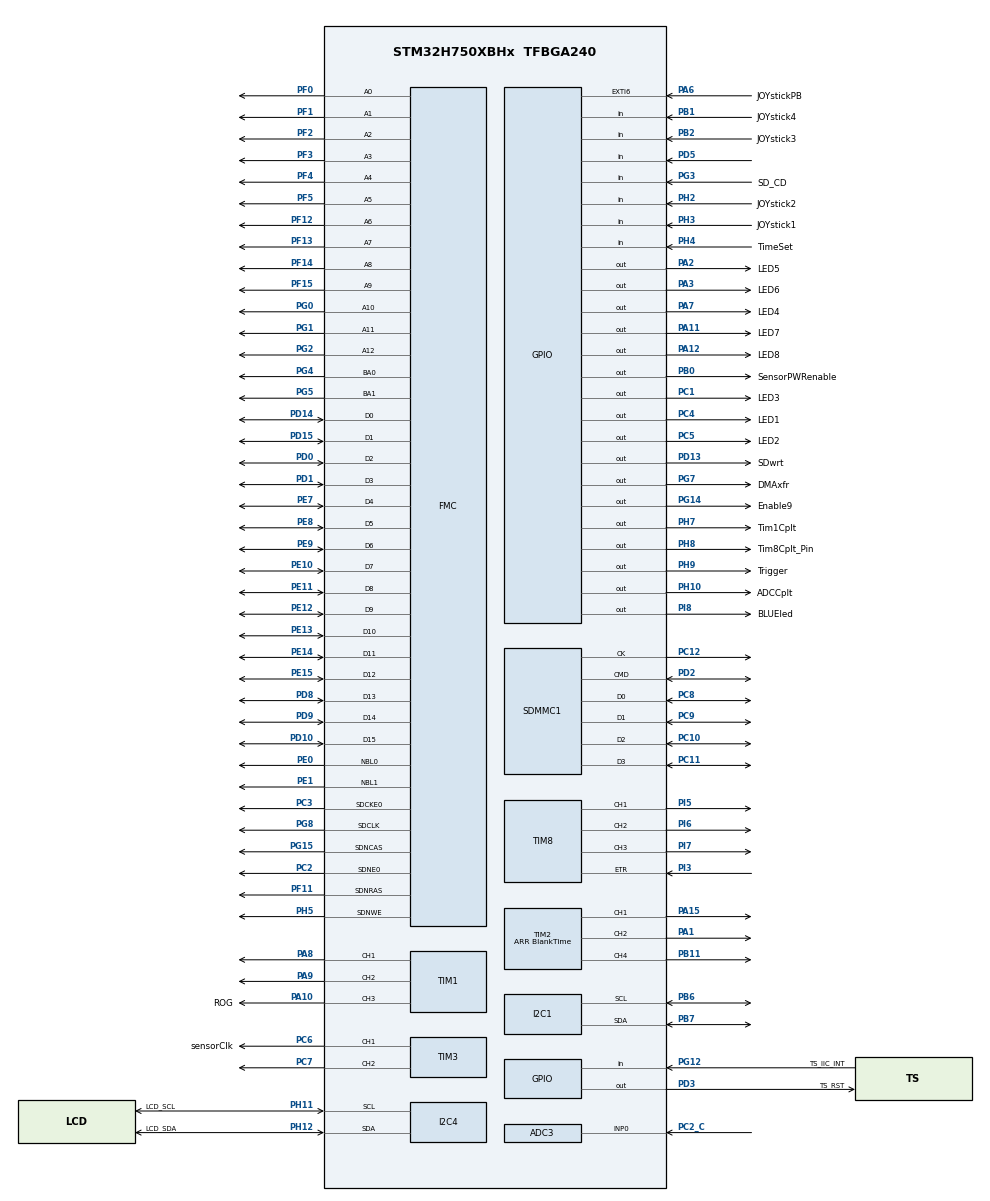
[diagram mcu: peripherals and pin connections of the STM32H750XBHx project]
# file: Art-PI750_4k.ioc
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ADC3.Channel-0\#ChannelRegularConversion=ADC_CHANNEL_0
ADC3.ClockPrescalerADC3=ADC_CLOCK_SYNC_PCLK_DIV1
ADC3.ConversionDataManagement=ADC_CONVERSIONDATA_DMA_CIRCULAR
ADC3.ExternalTrigConv=ADC_EXTERNALTRIG_T8_TRGO2
ADC3.ExternalTrigConvEdge=ADC_EXTERNALTRIGCONVEDGE_RISING
ADC3.LeftBitShift=ADC_LEFTBITSHIFT_4
ADC3.NbrOfConversionFlag=1
ADC3.OffsetNumber-0\#ChannelRegularConversion=ADC_OFFSET_NONE
ADC3.OffsetSignedSaturation-0\#ChannelRegularConversion=DISABLE
ADC3.Overrun=ADC_OVR_DATA_OVERWRITTEN
ADC3.Rank-0\#ChannelRegularConversion=1
ADC3.Resolution=ADC_RESOLUTION_12B
ADC3.SamplingTime-0\#ChannelRegularConversion=ADC_SAMPLETIME_1CYCLE_5
Bdma.I2C4_RX.1.Direction=DMA_PERIPH_TO_MEMORY
Bdma.I2C4_RX.1.EventEnable=DISABLE
Bdma.I2C4_RX.1.Instance=BDMA_Channel1
Bdma.I2C4_RX.1.MemDataAlignment=DMA_MDATAALIGN_BYTE
Bdma.I2C4_RX.1.MemInc=DMA_MINC_ENABLE
Bdma.I2C4_RX.1.Mode=DMA_NORMAL
Bdma.I2C4_RX.1.PeriphDataAlignment=DMA_PDATAALIGN_BYTE
Bdma.I2C4_RX.1.PeriphInc=DMA_PINC_DISABLE
Bdma.I2C4_RX.1.Polarity=HAL_DMAMUX_REQ_GEN_RISING
Bdma.I2C4_RX.1.Priority=DMA_PRIORITY_LOW
Bdma.I2C4_RX.1.RequestNumber=1
Bdma.I2C4_RX.1.SignalID=NONE
Bdma.I2C4_RX.1.SyncEnable=DISABLE
Bdma.I2C4_RX.1.SyncPolarity=HAL_DMAMUX_SYNC_NO_EVENT
Bdma.I2C4_RX.1.SyncRequestNumber=1
Bdma.I2C4_RX.1.SyncSignalID=NONE
Bdma.I2C4_TX.0.Direction=DMA_MEMORY_TO_PERIPH
Bdma.I2C4_TX.0.EventEnable=ENABLE
Bdma.I2C4_TX.0.Instance=BDMA_Channel0
Bdma.I2C4_TX.0.MemDataAlignment=DMA_MDATAALIGN_BYTE
Bdma.I2C4_TX.0.MemInc=DMA_MINC_ENABLE
Bdma.I2C4_TX.0.Mode=DMA_NORMAL
Bdma.I2C4_TX.0.PeriphDataAlignment=DMA_PDATAALIGN_BYTE
Bdma.I2C4_TX.0.PeriphInc=DMA_PINC_DISABLE
Bdma.I2C4_TX.0.Polarity=HAL_DMAMUX_REQ_GEN_RISING
Bdma.I2C4_TX.0.Priority=DMA_PRIORITY_LOW
Bdma.I2C4_TX.0.RequestNumber=1
Bdma.I2C4_TX.0.SignalID=NONE
Bdma.I2C4_TX.0.SyncEnable=DISABLE
Bdma.I2C4_TX.0.SyncPolarity=HAL_DMAMUX_SYNC_NO_EVENT
Bdma.I2C4_TX.0.SyncRequestNumber=1
Bdma.I2C4_TX.0.SyncSignalID=NONE
Bdma.Request0=I2C4_TX
Bdma.Request1=I2C4_RX
Bdma.RequestsNb=2
Dma.ADC3.1.Direction=DMA_PERIPH_TO_MEMORY
Dma.ADC3.1.EventEnable=DISABLE
Dma.ADC3.1.FIFOMode=DMA_FIFOMODE_ENABLE
Dma.ADC3.1.FIFOThreshold=DMA_FIFO_THRESHOLD_HALFFULL
Dma.ADC3.1.Instance=DMA2_Stream7
Dma.ADC3.1.MemBurst=DMA_MBURST_SINGLE
Dma.ADC3.1.MemDataAlignment=DMA_MDATAALIGN_HALFWORD
Dma.ADC3.1.MemInc=DMA_MINC_ENABLE
Dma.ADC3.1.Mode=DMA_CIRCULAR
Dma.ADC3.1.PeriphBurst=DMA_PBURST_SINGLE
Dma.ADC3.1.PeriphDataAlignment=DMA_PDATAALIGN_HALFWORD
Dma.ADC3.1.PeriphInc=DMA_PINC_DISABLE
Dma.ADC3.1.Polarity=HAL_DMAMUX_REQ_GEN_RISING
Dma.ADC3.1.Priority=DMA_PRIORITY_VERY_HIGH
Dma.ADC3.1.RequestNumber=1
Dma.ADC3.1.SignalID=NONE
Dma.ADC3.1.SyncEnable=DISABLE
Dma.ADC3.1.SyncPolarity=HAL_DMAMUX_SYNC_NO_EVENT
Dma.ADC3.1.SyncRequestNumber=1
Dma.ADC3.1.SyncSignalID=NONE
Dma.MEMTOMEM.0.Direction=DMA_MEMORY_TO_MEMORY
Dma.MEMTOMEM.0.EventEnable=DISABLE
Dma.MEMTOMEM.0.FIFOMode=DMA_FIFOMODE_ENABLE
Dma.MEMTOMEM.0.FIFOThreshold=DMA_FIFO_THRESHOLD_FULL
Dma.MEMTOMEM.0.Instance=DMA1_Stream7
Dma.MEMTOMEM.0.MemBurst=DMA_MBURST_INC4
Dma.MEMTOMEM.0.MemDataAlignment=DMA_MDATAALIGN_WORD
Dma.MEMTOMEM.0.MemInc=DMA_MINC_ENABLE
Dma.MEMTOMEM.0.Mode=DMA_NORMAL
Dma.MEMTOMEM.0.PeriphBurst=DMA_PBURST_INC4
Dma.MEMTOMEM.0.PeriphDataAlignment=DMA_PDATAALIGN_WORD
Dma.MEMTOMEM.0.PeriphInc=DMA_PINC_ENABLE
Dma.MEMTOMEM.0.Polarity=HAL_DMAMUX_REQ_GEN_RISING
Dma.MEMTOMEM.0.Priority=DMA_PRIORITY_VERY_HIGH
Dma.MEMTOMEM.0.RequestNumber=1
Dma.MEMTOMEM.0.SignalID=NONE
Dma.MEMTOMEM.0.SyncEnable=DISABLE
Dma.MEMTOMEM.0.SyncPolarity=HAL_DMAMUX_SYNC_NO_EVENT
Dma.MEMTOMEM.0.SyncRequestNumber=1
Dma.MEMTOMEM.0.SyncSignalID=NONE
Dma.Request0=MEMTOMEM
Dma.Request1=ADC3
FATFS.BSP.number=1
FATFS.USE_DMA_CODE_SD=1
FATFS._FS_EXFAT=1
FATFS._USE_LFN=1
FATFS0.BSP.STBoard=false
FATFS0.BSP.api=Unknown
FATFS0.BSP.instance=PG3
FATFS0.BSP.ip=GPIO
FATFS0.BSP.mode=Input
FATFS0.BSP.name=Detect_SDIO
FATFS0.BSP.solution=PG3
FMC.CASLatency1=FMC_SDRAM_CAS_LATENCY_2
FMC.ColumnBitsNumber1=FMC_SDRAM_COLUMN_BITS_NUM_9
FMC.ExitSelfRefreshDelay1=7
FMC.LoadToActiveDelay1=2
FMC.RCDDelay1=2
FMC.RPDelay1=2
FMC.ReadBurst1=FMC_SDRAM_RBURST_ENABLE
FMC.ReadPipeDelay1=FMC_SDRAM_RPIPE_DELAY_2
FMC.ReadPipeDelay2=FMC_SDRAM_RPIPE_DELAY_2
FMC.RowCycleDelay1=6
FMC.RowCycleDelay2=6
FMC.SDClockPeriod1=FMC_SDRAM_CLOCK_PERIOD_2
FMC.SDClockPeriod2=FMC_SDRAM_CLOCK_PERIOD_2
FMC.SelfRefreshTime1=5
FMC.WriteRecoveryTime1=3
I2C1.Timing=0x00C0EAFF
Mcu.Family=STM32H7
Mcu.Name=STM32H750XBHx
Mcu.Package=TFBGA240
Mcu.UserConstants=BlankTime,(1800-1);Usec,100;TIMEDenom,8;Exposure,(8000);NumLines,1000;TIMENumer,5;Npixels,4096
Mdma.MDMA_Channel0.Request0=SDMMC1_COMMAND_END
Mdma.MDMA_Channel0.RequestsNb=1
Mdma.MDMA_Channel0.SDMMC1_COMMAND_END.0.BlockCount=0
Mdma.MDMA_Channel0.SDMMC1_COMMAND_END.0.BlockDataLength=0
Mdma.MDMA_Channel0.SDMMC1_COMMAND_END.0.BufferTransferLength=1
Mdma.MDMA_Channel0.SDMMC1_COMMAND_END.0.CircularMode=MDMA_LINEAR_LIST
Mdma.MDMA_Channel0.SDMMC1_COMMAND_END.0.DataAlignment=MDMA_DATAALIGN_PACKENABLE
Mdma.MDMA_Channel0.SDMMC1_COMMAND_END.0.DestBlockAddressOffset=0
Mdma.MDMA_Channel0.SDMMC1_COMMAND_END.0.DestBurst=MDMA_DEST_BURST_SINGLE
Mdma.MDMA_Channel0.SDMMC1_COMMAND_END.0.DestDataSize=MDMA_DEST_DATASIZE_WORD
Mdma.MDMA_Channel0.SDMMC1_COMMAND_END.0.DestinationInc=MDMA_DEST_INC_WORD
Mdma.MDMA_Channel0.SDMMC1_COMMAND_END.0.DstAddress=0
Mdma.MDMA_Channel0.SDMMC1_COMMAND_END.0.Endianness=MDMA_LITTLE_ENDIANNESS_PRESERVE
Mdma.MDMA_Channel0.SDMMC1_COMMAND_END.0.Instance=MDMA_Channel0
Mdma.MDMA_Channel0.SDMMC1_COMMAND_END.0.MaskAddress=0
Mdma.MDMA_Channel0.SDMMC1_COMMAND_END.0.MaskData=0
Mdma.MDMA_Channel0.SDMMC1_COMMAND_END.0.Priority=MDMA_PRIORITY_LOW
Mdma.MDMA_Channel0.SDMMC1_COMMAND_END.0.Rank=First
Mdma.MDMA_Channel0.SDMMC1_COMMAND_END.0.SourceBlockAddressOffset=0
Mdma.MDMA_Channel0.SDMMC1_COMMAND_END.0.SourceBurst=MDMA_SOURCE_BURST_SINGLE
Mdma.MDMA_Channel0.SDMMC1_COMMAND_END.0.SourceDataSize=MDMA_SRC_DATASIZE_WORD
Mdma.MDMA_Channel0.SDMMC1_COMMAND_END.0.SourceInc=MDMA_SRC_INC_WORD
Mdma.MDMA_Channel0.SDMMC1_COMMAND_END.0.SrcAddress=0
Mdma.MDMA_Channel0.SDMMC1_COMMAND_END.0.TransferTriggerMode=MDMA_BUFFER_TRANSFER
Mdma.RequestSet0=MDMA_Channel0
Mdma.RequestSetsNb=1
NVIC.ADC3_IRQn=true\:0\:0\:false\:false\:true\:true\:true\:true
NVIC.BDMA_Channel0_IRQn=true\:0\:0\:false\:false\:true\:false\:true\:true
NVIC.BDMA_Channel1_IRQn=true\:0\:0\:false\:false\:true\:false\:true\:true
NVIC.DMA1_Stream7_IRQn=true\:0\:0\:false\:false\:true\:true\:true\:true
NVIC.DMA2_Stream7_IRQn=true\:0\:0\:false\:false\:true\:false\:true\:true
NVIC.DMAMUX2_OVR_IRQn=true\:0\:0\:false\:false\:true\:false\:true\:true
NVIC.I2C4_ER_IRQn=true\:0\:0\:false\:false\:true\:true\:true\:true
NVIC.I2C4_EV_IRQn=true\:0\:0\:false\:false\:true\:true\:true\:true
NVIC.MDMA_IRQn=true\:0\:0\:false\:false\:true\:false\:true\:true
NVIC.PriorityGroup=NVIC_PRIORITYGROUP_4
NVIC.SDMMC1_IRQn=true\:0\:0\:false\:false\:true\:true\:true\:true
NVIC.TIM1_TRG_COM_IRQn=true\:0\:0\:false\:false\:true\:true\:true\:true
NVIC.TIM1_UP_IRQn=true\:0\:0\:false\:false\:true\:true\:true\:true
NVIC.TIM2_IRQn=true\:0\:0\:false\:false\:true\:true\:true\:true
NVIC.TIM3_IRQn=true\:0\:0\:false\:false\:true\:true\:true\:true
NVIC.TIM8_TRG_COM_TIM14_IRQn=true\:0\:0\:false\:false\:true\:true\:true\:true
NVIC.TIM8_UP_TIM13_IRQn=true\:0\:0\:false\:false\:true\:true\:true\:true
PA1.GPIO_Speed=GPIO_SPEED_FREQ_HIGH
PA1.Signal=S_TIM2_CH2
PA10.GPIO_Label=ROG
PA10.GPIO_Speed=GPIO_SPEED_FREQ_HIGH
PA10.Signal=S_TIM1_CH3
PA11.GPIO_Label=LED7
PA11.Signal=GPIO_Output
PA12.GPIO_Label=LED8
PA12.Signal=GPIO_Output
PA15\ (JTDI).GPIO_Speed=GPIO_SPEED_FREQ_HIGH
PA15\ (JTDI).Signal=S_TIM2_CH1_ETR
PA2.GPIO_Label=LED5
PA2.Signal=GPIO_Output
PA3.GPIO_Label=LED6
PA3.GPIO_PuPd=GPIO_PULLDOWN
PA3.Signal=GPIO_Output
PA6.GPIO_Label=JOYstickPB
PA6.GPIO_PuPd=GPIO_PULLUP
PA6.Signal=GPXTI6
PA7.GPIO_Label=LED4
PA7.Signal=GPIO_Output
PA8.GPIO_Speed=GPIO_SPEED_FREQ_HIGH
PA8.Signal=S_TIM1_CH1
PA9.GPIO_Speed=GPIO_SPEED_FREQ_HIGH
PA9.Signal=S_TIM1_CH2
PB0.GPIO_Label=SensorPWRenable
PB0.PinState=GPIO_PIN_SET
PB0.Signal=GPIO_Output
PB1.GPIO_Label=JOYstick4
PB1.GPIO_PuPd=GPIO_PULLUP
PB1.Signal=GPIO_Input
PB10.Signal=USART3_TX
PB11.Signal=S_TIM2_CH4
PB2.GPIO_Label=JOYstick3
PB2.GPIO_PuPd=GPIO_PULLUP
PB2.Signal=GPIO_Input
PB3\ (JTDO/TRACESWO).Signal=SDMMC2_D2
PB6.Mode=I2C
PB6.Signal=I2C1_SCL
PB7.Mode=I2C
PB7.Signal=I2C1_SDA
PC1.GPIO_Label=LED3
PC1.Signal=GPIO_Output
PC10.Mode=SD_4_bits_Wide_bus
PC10.Signal=SDMMC1_D2
PC11.Mode=SD_4_bits_Wide_bus
PC11.Signal=SDMMC1_D3
PC12.Mode=SD_4_bits_Wide_bus
PC12.Signal=SDMMC1_CK
PC14-OSC32_IN\ (OSC32_IN).Mode=LSE-External-Oscillator
PC14-OSC32_IN\ (OSC32_IN).Signal=RCC_OSC32_IN
PC15-OSC32_OUT\ (OSC32_OUT).Mode=LSE-External-Oscillator
PC15-OSC32_OUT\ (OSC32_OUT).Signal=RCC_OSC32_OUT
PC2.Mode=SdramChipSelect1_1
PC2.Signal=FMC_SDNE0
PC2_C.Mode=IN0-Single-Ended
PC2_C.Signal=ADC3_INP0
PC3.Mode=SdramChipSelect1_1
PC3.Signal=FMC_SDCKE0
PC4.GPIO_Label=LED1
PC4.Signal=GPIO_Output
PC5.GPIO_Label=LED2
PC5.Signal=GPIO_Output
PC6.GPIO_Label=sensorClk
PC6.GPIO_Speed=GPIO_SPEED_FREQ_HIGH
PC6.Signal=S_TIM3_CH1
PC7.GPIO_Speed=GPIO_SPEED_FREQ_HIGH
PC7.Signal=S_TIM3_CH2
PC8.Mode=SD_4_bits_Wide_bus
PC8.Signal=SDMMC1_D0
PC9.Mode=SD_4_bits_Wide_bus
PC9.Signal=SDMMC1_D1
PD0.Signal=FMC_D2_DA2
PD1.Signal=FMC_D3_DA3
PD10.Signal=FMC_D15_DA15
PD13.GPIO_Label=SDwrt
PD13.Signal=GPIO_Output
PD14.Signal=FMC_D0_DA0
PD15.Signal=FMC_D1_DA1
PD2.Mode=SD_4_bits_Wide_bus
PD2.Signal=SDMMC1_CMD
PD3.GPIO_Label=TS_RST
PD3.Signal=GPIO_Output
PD5.Signal=GPIO_Input
PD8.Signal=FMC_D13_DA13
PD9.Signal=FMC_D14_DA14
PE0.Signal=FMC_NBL0
PE1.Signal=FMC_NBL1
PE10.Signal=FMC_D7_DA7
PE11.Signal=FMC_D8_DA8
PE12.Signal=FMC_D9_DA9
PE13.Signal=FMC_D10_DA10
PE14.Signal=FMC_D11_DA11
PE15.Signal=FMC_D12_DA12
PE7.Signal=FMC_D4_DA4
PE8.Signal=FMC_D5_DA5
PE9.Signal=FMC_D6_DA6
PF0.Signal=FMC_A0
PF1.Signal=FMC_A1
PF11.Signal=FMC_SDNRAS
PF12.Signal=FMC_A6
PF13.Signal=FMC_A7
PF14.Signal=FMC_A8
PF15.Signal=FMC_A9
PF2.Signal=FMC_A2
PF3.Signal=FMC_A3
PF4.Signal=FMC_A4
PF5.Signal=FMC_A5
PF7.Signal=QUADSPI_BK1_IO2
PG0.Signal=FMC_A10
PG1.Signal=FMC_A11
PG12.GPIO_Label=TS_IIC_INT
PG12.GPIO_PuPd=GPIO_PULLUP
PG12.Signal=GPIO_Input
PG14.GPIO_Label=Enable9
PG14.GPIO_PuPd=GPIO_PULLUP
PG14.Signal=GPIO_Output
PG15.Signal=FMC_SDNCAS
PG2.Signal=FMC_A12
PG3.GPIO_Label=SD_CD
PG3.GPIO_PuPd=GPIO_PULLDOWN
PG3.Signal=GPIO_Input
PG4.Signal=FMC_A14_BA0
PG5.Signal=FMC_A15_BA1
PG6.Signal=QUADSPI_BK1_NCS
PG7.GPIO_Label=DMAxfr
PG7.Signal=GPIO_Output
PG8.Signal=FMC_SDCLK
PH0-OSC_IN\ (PH0).Mode=HSE-External-Oscillator
PH0-OSC_IN\ (PH0).Signal=RCC_OSC_IN
PH1-OSC_OUT\ (PH1).Mode=HSE-External-Oscillator
PH1-OSC_OUT\ (PH1).Signal=RCC_OSC_OUT
PH10.GPIO_Label=ADCCplt
PH10.Signal=GPIO_Output
PH11.GPIO_Label=LCD_SCL
PH11.Mode=I2C
PH11.Signal=I2C4_SCL
PH12.GPIO_Label=LCD_SDA
PH12.Mode=I2C
PH12.Signal=I2C4_SDA
PH2.GPIO_Label=JOYstick2
PH2.GPIO_PuPd=GPIO_PULLUP
PH2.Signal=GPIO_Input
PH3.GPIO_Label=JOYstick1
PH3.GPIO_PuPd=GPIO_PULLUP
PH3.Signal=GPIO_Input
PH4.GPIO_Label=TimeSet
PH4.Signal=GPIO_Input
PH5.Signal=FMC_SDNWE
PH7.GPIO_Label=Tim1Cplt
PH7.Signal=GPIO_Output
PH8.GPIO_Label=Tim8Cplt_Pin
PH8.Signal=GPIO_Output
PH9.GPIO_Label=Trigger
PH9.Signal=GPIO_Output
PI12.Signal=LTDC_HSYNC
PI13.Signal=LTDC_VSYNC
PI14.Signal=LTDC_CLK
PI15.Signal=LTDC_R0
PI3.Signal=S_TIM8_ETR
PI5.GPIO_Speed=GPIO_SPEED_FREQ_HIGH
PI5.Signal=S_TIM8_CH1
PI6.Signal=S_TIM8_CH2
PI7.Signal=S_TIM8_CH3
PI8.GPIO_Label=BLUEled
PI8.GPIO_PuPd=GPIO_PULLUP
PI8.Signal=GPIO_Output
PJ0.Signal=LTDC_R1
PJ1.Signal=LTDC_R2
PJ10.Signal=LTDC_G3
PJ11.Signal=LTDC_G4
PJ12.Signal=LTDC_B0
PJ13.Signal=LTDC_B1
PJ2.Signal=LTDC_R3
PJ3.Signal=LTDC_R4
PJ4.Signal=LTDC_R5
PJ6.Signal=LTDC_R7
PJ7.Signal=LTDC_G0
PJ8.Signal=LTDC_G1
PJ9.Signal=LTDC_G2
PK1.Signal=LTDC_G6
PK2.Signal=LTDC_G7
PK3.Signal=LTDC_B4
PK4.Signal=LTDC_B5
PK5.Signal=LTDC_B6
PK6.Signal=LTDC_B7
ProjectManager.HeapSize=0x800
ProjectManager.StackSize=0x1600
ProjectManager.TargetToolchain=STM32CubeIDE
RCC.ADCCLockSelection=RCC_ADCCLKSOURCE_PLL3
RCC.ADCFreq_Value=37500000
RCC.APB1Freq_Value=50000000
RCC.APB2Freq_Value=50000000
RCC.APB3Freq_Value=100000000
RCC.APB4Freq_Value=100000000
RCC.CortexFreq_Value=400000000
RCC.D1PPRE=RCC_APB3_DIV2
RCC.D2PPRE1=RCC_APB1_DIV4
RCC.D2PPRE2=RCC_APB2_DIV4
RCC.D3PPRE=RCC_APB4_DIV2
RCC.DIVM1=5
RCC.DIVM2=25
RCC.DIVM3=5
RCC.DIVN1=160
RCC.DIVN2=192
RCC.DIVN3=30
RCC.DIVP2=4
RCC.DIVQ1=20
RCC.DIVR2=5
RCC.DIVR3=4
RCC.FMCCLockSelection=RCC_FMCCLKSOURCE_PLL
RCC.HCLKFreq_Value=200000000
RCC.HPRE=RCC_HCLK_DIV2
RCC.I2C4CLockSelection=RCC_I2C4CLKSOURCE_HSI
RCC.PLLSourceVirtual=RCC_PLLSOURCE_HSE
RCC.PWR_Regulator_Voltage_Scale=PWR_REGULATOR_VOLTAGE_SCALE1
RCC.QSPICLockSelection=RCC_QSPICLKSOURCE_PLL
RCC.RTCClockSelection=RCC_RTCCLKSOURCE_LSE
RCC.SYSCLKFreq_VALUE=400000000
RCC.SYSCLKSource=RCC_SYSCLKSOURCE_PLLCLK
RCC.USBFreq_Value=40000000
RTC.Date=2
RTC.Hours=13
RTC.Minutes=30
RTC.Month=RTC_MONTH_NOVEMBER
RTC.StoreOperation=RTC_STOREOPERATION_SET
RTC.WeekDay=RTC_WEEKDAY_SUNDAY
RTC.Year=23
SDMMC1.ClockDiv=2
SDMMC1.HardwareFlowControl=SDMMC_HARDWARE_FLOW_CONTROL_DISABLE
SH.FMC_A0.0=FMC_A0,13b-sda1
SH.FMC_A1.0=FMC_A1,13b-sda1
SH.FMC_A10.0=FMC_A10,13b-sda1
SH.FMC_A11.0=FMC_A11,13b-sda1
SH.FMC_A12.0=FMC_A12,13b-sda1
SH.FMC_A14_BA0.0=FMC_BA0,FourSdramBanks1
SH.FMC_A15_BA1.0=FMC_BA1,FourSdramBanks1
SH.FMC_A2.0=FMC_A2,13b-sda1
SH.FMC_A3.0=FMC_A3,13b-sda1
SH.FMC_A4.0=FMC_A4,13b-sda1
SH.FMC_A5.0=FMC_A5,13b-sda1
SH.FMC_A6.0=FMC_A6,13b-sda1
SH.FMC_A7.0=FMC_A7,13b-sda1
SH.FMC_A8.0=FMC_A8,13b-sda1
SH.FMC_A9.0=FMC_A9,13b-sda1
SH.FMC_D0_DA0.0=FMC_D0,sd-16b-d1
SH.FMC_D10_DA10.0=FMC_D10,sd-16b-d1
SH.FMC_D11_DA11.0=FMC_D11,sd-16b-d1
SH.FMC_D12_DA12.0=FMC_D12,sd-16b-d1
SH.FMC_D13_DA13.0=FMC_D13,sd-16b-d1
SH.FMC_D14_DA14.0=FMC_D14,sd-16b-d1
SH.FMC_D15_DA15.0=FMC_D15,sd-16b-d1
SH.FMC_D1_DA1.0=FMC_D1,sd-16b-d1
SH.FMC_D2_DA2.0=FMC_D2,sd-16b-d1
SH.FMC_D3_DA3.0=FMC_D3,sd-16b-d1
SH.FMC_D4_DA4.0=FMC_D4,sd-16b-d1
SH.FMC_D5_DA5.0=FMC_D5,sd-16b-d1
SH.FMC_D6_DA6.0=FMC_D6,sd-16b-d1
SH.FMC_D7_DA7.0=FMC_D7,sd-16b-d1
SH.FMC_D8_DA8.0=FMC_D8,sd-16b-d1
SH.FMC_D9_DA9.0=FMC_D9,sd-16b-d1
SH.FMC_NBL0.0=FMC_NBL0,Sd2ByteEnable1
SH.FMC_NBL1.0=FMC_NBL1,Sd2ByteEnable1
SH.FMC_SDCLK.0=FMC_SDCLK,13b-sda1
SH.FMC_SDNCAS.0=FMC_SDNCAS,13b-sda1
SH.FMC_SDNRAS.0=FMC_SDNRAS,13b-sda1
SH.FMC_SDNWE.0=FMC_SDNWE,13b-sda1
SH.S_TIM1_CH1.0=TIM1_CH1,PWM Generation1 CH1
SH.S_TIM1_CH2.0=TIM1_CH2,PWM Generation2 CH2
SH.S_TIM1_CH3.0=TIM1_CH3,PWM Generation3 CH3
SH.S_TIM2_CH1_ETR.0=TIM2_CH1,PWM Generation1 CH1
SH.S_TIM2_CH2.0=TIM2_CH2,PWM Generation2 CH2
SH.S_TIM2_CH4.0=TIM2_CH4,PWM Generation4 CH4
SH.S_TIM3_CH1.0=TIM3_CH1,PWM Generation1 CH1
SH.S_TIM3_CH2.0=TIM3_CH2,PWM Generation2 CH2
SH.S_TIM8_CH1.0=TIM8_CH1,PWM Generation1 CH1
SH.S_TIM8_CH2.0=TIM8_CH2,PWM Generation2 CH2
SH.S_TIM8_CH3.0=TIM8_CH3,PWM Generation3 CH3
SH.S_TIM8_ETR.0=TIM8_ETR,TriggerSource_ETR
TIM1.AutoReloadPreload=TIM_AUTORELOAD_PRELOAD_ENABLE
TIM1.Channel-PWM\ Generation1\ CH1=TIM_CHANNEL_1
TIM1.Channel-PWM\ Generation2\ CH2=TIM_CHANNEL_2
TIM1.Channel-PWM\ Generation3\ CH3=TIM_CHANNEL_3
TIM1.OC2Preload_PWM=ENABLE
TIM1.OCFastMode_PWM-PWM\ Generation2\ CH2=TIM_OCFAST_ENABLE
TIM1.OCFastMode_PWM-PWM\ Generation3\ CH3=TIM_OCFAST_ENABLE
TIM1.OCIdleState_2=TIM_OCIDLESTATE_RESET
TIM1.OCMode_PWM-PWM\ Generation1\ CH1=TIM_OCMODE_PWM2
TIM1.OCMode_PWM-PWM\ Generation2\ CH2=TIM_OCMODE_PWM2
TIM1.OCMode_PWM-PWM\ Generation3\ CH3=TIM_OCMODE_PWM2
TIM1.OCPolarity_1=TIM_OCPOLARITY_LOW
TIM1.OCPolarity_2=TIM_OCPOLARITY_LOW
TIM1.OCPolarity_3=TIM_OCPOLARITY_LOW
TIM1.Period=((Exposure*TIMEDenom/TIMENumer)-1)
TIM1.Prescaler=((Usec*TIMENumer/TIMEDenom)-1)
TIM1.Pulse-PWM\ Generation1\ CH1=4
TIM1.Pulse-PWM\ Generation2\ CH2=3
TIM1.Pulse-PWM\ Generation3\ CH3=3
TIM1.RepetitionCounter=NumLines
TIM1.TIM_MasterOutputTrigger=TIM_TRGO_OC1REF
TIM1.TIM_MasterOutputTrigger2=TIM_TRGO2_UPDATE
TIM1.TIM_MasterSlaveMode=TIM_MASTERSLAVEMODE_ENABLE
TIM2.Channel-PWM\ Generation1\ CH1=TIM_CHANNEL_1
TIM2.Channel-PWM\ Generation2\ CH2=TIM_CHANNEL_2
TIM2.Channel-PWM\ Generation4\ CH4=TIM_CHANNEL_4
TIM2.OCFastMode_PWM-PWM\ Generation1\ CH1=TIM_OCFAST_ENABLE
TIM2.OCFastMode_PWM-PWM\ Generation2\ CH2=TIM_OCFAST_ENABLE
TIM2.OCMode_PWM-PWM\ Generation1\ CH1=TIM_OCMODE_PWM2
TIM2.OCMode_PWM-PWM\ Generation2\ CH2=TIM_OCMODE_PWM1
TIM2.OCPolarity_1=TIM_OCPOLARITY_HIGH
TIM2.Period=BlankTime
TIM2.Pulse-PWM\ Generation1\ CH1=Usec/3-1
TIM2.Pulse-PWM\ Generation2\ CH2=(Usec/4) -1
TIM2.TIM_MasterSlaveMode=TIM_MASTERSLAVEMODE_ENABLE
TIM3.Channel-PWM\ Generation1\ CH1=TIM_CHANNEL_1
TIM3.Channel-PWM\ Generation2\ CH2=TIM_CHANNEL_2
TIM3.OCMode_PWM-PWM\ Generation2\ CH2=TIM_OCMODE_PWM1
TIM3.OCPolarity_1=TIM_OCPOLARITY_HIGH
TIM3.OCPolarity_2=TIM_OCPOLARITY_HIGH
TIM3.Period=(Usec*TIMENumer/TIMEDenom-1)
TIM3.Pulse-PWM\ Generation1\ CH1=((Usec/4)-1)
TIM3.Pulse-PWM\ Generation2\ CH2=(((Usec/4))-1)
TIM3.TIM_MasterOutputTrigger=TIM_TRGO_OC3REF
TIM8.Channel-PWM\ Generation1\ CH1=TIM_CHANNEL_1
TIM8.Channel-PWM\ Generation2\ CH2=TIM_CHANNEL_2
TIM8.Channel-PWM\ Generation3\ CH3=TIM_CHANNEL_3
TIM8.OCFastMode_PWM-PWM\ Generation1\ CH1=TIM_OCFAST_ENABLE
TIM8.OCFastMode_PWM-PWM\ Generation2\ CH2=TIM_OCFAST_ENABLE
TIM8.OCFastMode_PWM-PWM\ Generation3\ CH3=TIM_OCFAST_ENABLE
TIM8.OCMode_PWM-PWM\ Generation1\ CH1=TIM_OCMODE_PWM2
TIM8.OCMode_PWM-PWM\ Generation2\ CH2=TIM_OCMODE_PWM2
TIM8.OCMode_PWM-PWM\ Generation3\ CH3=TIM_OCMODE_PWM2
TIM8.Period=(Usec*TIMENumer/TIMEDenom)-1
TIM8.Pulse-PWM\ Generation1\ CH1=((Usec/4)-1)
TIM8.Pulse-PWM\ Generation2\ CH2=2
TIM8.Pulse-PWM\ Generation3\ CH3=2
TIM8.RepetitionCounter=Npixels-1
TIM8.TIM_MasterOutputTrigger=TIM_TRGO_UPDATE
TIM8.TIM_MasterOutputTrigger2=TIM_TRGO2_OC1REF
TIM8.TIM_MasterSlaveMode=TIM_MASTERSLAVEMODE_ENABLE
VP_FATFS_VS_SDIO.Mode=SDIO
VP_MEMORYMAP_VS_MEMORYMAP.Mode=CurAppReg
VP_RTC_VS_RTC_Activate.Mode=RTC_Enabled
VP_RTC_VS_RTC_Calendar.Mode=RTC_Calendar
VP_TIM1_VS_ClockSourceINT.Mode=Internal
VP_TIM1_VS_OPM.Mode=OPM_bit
VP_TIM2_VS_ClockSourceINT.Mode=Internal
VP_TIM2_VS_ClockSourceITR.Mode=TriggerSource_ITR0
VP_TIM2_VS_ControllerModeTrigger.Mode=Trigger Mode
VP_TIM2_VS_OPM.Mode=OPM_bit
VP_TIM3_VS_ClockSourceINT.Mode=Internal
VP_TIM3_VS_ClockSourceITR.Mode=TriggerSource_ITR0
VP_TIM3_VS_ControllerModeGated.Mode=Gated Mode
VP_TIM8_VS_ClockSourceINT.Mode=Internal
VP_TIM8_VS_ControllerModeTrigger.Mode=Trigger Mode
VP_TIM8_VS_OPM.Mode=OPM_bit
VP_VREFBUF_V_VREFBUF.Mode=ExternalMode
board=custom

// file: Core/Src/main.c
/* USER CODE BEGIN Header */
/**
 ******************************************************************************
 * @file           : main.c
 * @brief          : Main program body
 ******************************************************************************
 * @attention
 *
 * Timer rational
 * Tim1 -> Master clock 				Provides ROG
 * Tim2 -> Blank time Tiggered by #1
 * Tim3 -> Gatemode   Triggered by #2  	Provides SensorClk
 * Tim8 -> 								Provides  trigger Ext trigger by 3 to ADC
 * ADC triggers DMA to Buffer D2
 * ADC Complete triggers DMA from D2 to SDram
 *
 *
 *
 ******************************************************************************
 */
/* USER CODE END Header */
#include "main.h"
#include "adc.h"
#include "bdma.h"
#include "dma.h"
#include "fatfs.h"
#include "i2c.h"
#include "mdma.h"
#include "memorymap.h"
#include "rtc.h"
#include "sdmmc.h"
#include "tim.h"
#include "gpio.h"
#include "fmc.h"

/* USER CODE BEGIN Includes */
#include <stdio.h>
#include <string.h>
#include "memtest.h"
#include "ssd1306.h"

/* USER CODE END Includes */

/* USER CODE BEGIN PD */
#define DMA_BUFFER   __attribute__((section(".sdram")))
#define DMAd2BUFFER   __attribute__((section(".dma_buffer")))

#define DMABUFFLEN (Npixels*2)

#define SLOTS ((30*1024*1024 /(Npixels*2)))
//#define TIMENumer 6
//#define TIMEDenom 8
#define ONEPWR
//#define  WRSLOTS 16

enum Seq{ SEQ_Ready=0,SEQ_Running,SEQ_ONgoing,SEQ_Complete};
enum ADC_state{ADC_idle,ADC_1half,ADC_2half };
enum SD_state{SDnotopen,SDopen};
enum SelectN_slc{SelectNNOTSelectNed,SelectNSelectNed};
enum ChoiceS{SelectN_RUN,SelectN_EXP,SelectN_LGTH};
enum XferReady {NotReady,Ready};
enum RUNSTATE {CONTINUOUS,SINGLE,HISTOGRAM,HALT};
//#define HALFCPLT_ADC_GPIO 	HAL_GPIO_TogglePin(ADChalfCplt_GPIO_Port, ADChalfCplt_Pin);

#define CPLT_TIM1pe_GPIO	HAL_GPIO_TogglePin(GPIOH, Tim1Cplt_Pin)
#define CPLT_TIM8pe_GPIO	HAL_GPIO_TogglePin(GPIOH, Tim8Cplt_Pin)
#define CPLT_ADC_GPIO		HAL_GPIO_TogglePin(GPIOH, ADCCplt_Pin)

#define TRIGGER_TIM1_GPIO	HAL_GPIO_TogglePin(GPIOH, Trigger_Pin)
#define DMA_XFR_CPLT_GPIO   HAL_GPIO_TogglePin(GPIOG, DMAxfr_Pin)
#define SD_WriteStartTime   HAL_GPIO_TogglePin(GPIOD, SDwrt_Pin)

#define SDRAMAREA 0xc0000000

#define DISK
#define  LCD_ShowString(a, b, c,d, e, f) {ssd1306_SetCursor(a, b); ssd1306_WriteString(f, Font_7x10);	   ssd1306_UpdateScreen();}
/* USER CODE END PD */

/* USER CODE BEGIN PV */

volatile uint16_t  *DMA_2nBuffer;
FIL fp;
char rtext[_MAX_SS] = "1234567890 1234567890 ";;
//char whitespace [234];
char fileHeadertext[_MAX_SS];
uint8_t FontH;// = Font_7x10.FontHeight;
GPIO_PinState buttonState=0;
GPIO_PinState oldState=0;
uint8_t Sequence=SEQ_Ready;
uint8_t ADCstate=ADC_idle;
uint8_t SDstate=SDnotopen;
uint8_t RunState = HALT;
uint8_t xferState = NotReady;
int8_t MenuItem =0;
int8_t SelectNEState = 1;
uint16_t SelectNEStateValue[]={6000,7000,8000,9000,10000,12000};
int8_t SelectNLState = 2;
uint16_t SelectNLStateValue[]={4096,8192,16384,32768};

char RunType[]={'C','S','H'};
uint8_t SelectRT=2;
uint32_t DACval=0;

FRESULT f_err_code;
static FATFS FATFS_Obj;

int Nfilename=0;
FIL fp;
uint32_t BytesWritten=0;
int hlen;
volatile DMAd2BUFFER uint16_t dmaBuffer[DMABUFFLEN];

#ifdef Exposure
#undef Exposure
#undef NumLines
#endif
uint32_t Exposure ;
uint32_t NumLines ;
RTC_TimeTypeDef timeStart;
RTC_TimeTypeDef timeEnd;
RTC_TimeTypeDef Filetime;
uint32_t secStart=0;
uint16_t lastpixel=0;
volatile uint32_t IRQCNT_HAL_UART_TxCpltCallback=0;
volatile uint32_t IRQCNT_HAL_ADC_ConvCpltCallback=0;
volatile uint32_t IRQCNT_HAL_TIM_PeriodElapsedHalfCpltCallback1=0;
volatile uint32_t IRQCNT_HAL_TIM_PeriodElapsedHalfCpltCallback2=0;
volatile uint32_t IRQCNT_HAL_TIM_PeriodElapsedHalfCpltCallback3=0;
volatile uint32_t IRQCNT_HAL_TIM_PeriodElapsedHalfCpltCallback8=0;
volatile uint32_t IRQCNT_HAL_TIM_PeriodElapsedCallback1=0;
volatile uint32_t IRQCNT_HAL_TIM_PeriodElapsedCallback2=0;
volatile uint32_t IRQCNT_HAL_TIM_PeriodElapsedCallback3=0;
volatile uint32_t IRQCNT_HAL_TIM_PeriodElapsedCallback8=0;
volatile uint32_t IRQCNT_HAL_TIM_TriggerCallback1=0;
volatile uint32_t IRQCNT_HAL_TIM_TriggerCallback2=0;
volatile uint32_t IRQCNT_HAL_TIM_TriggerCallback3=0;
volatile uint32_t IRQCNT_HAL_TIM_TriggerCallback8=0;

volatile uint32_t TransferComplete7=0;
volatile uint32_t TransferCompleteelse=0;

volatile uint32_t HAL_GPIO_EXTI_CallbackK1=0;
volatile uint32_t HAL_GPIO_EXTI_CallbackSelectN=0;

volatile uint32_t HAL_GPIO_EXTI_CallbackNxt=0;

volatile uint32_t pixelPlaceOld, pixelPlace;
volatile uint32_t BuffDiff=0,BuffDiffMax=0;
volatile uint32_t CurrentSlot=0;
volatile uint32_t LastWrittenSlot=0;
volatile uint32_t NumberOfWrites=0;

/* USER CODE END PV */

void SystemClock_Config(void);
/* USER CODE BEGIN PFP */
void TransferComplete(DMA_HandleTypeDef *hdma);
void TransferError(DMA_HandleTypeDef *hdma);
void TrialEnd(void);
/* USER CODE END PFP */

/* USER CODE BEGIN 0 */

int RTC_Set(
		uint8_t year, uint8_t month, uint8_t day,
		uint8_t hour, uint8_t min)
{
	HAL_StatusTypeDef res;
	RTC_TimeTypeDef time;
	RTC_DateTypeDef date;

	memset(&time, 0, sizeof(time));
	memset(&date, 0, sizeof(date));

	date.WeekDay = 0;
	date.Year = year;
	date.Month = month;
	date.Date = day;

	res = HAL_RTC_SetDate(&hrtc, &date, RTC_FORMAT_BIN);
	if(res != HAL_OK) {
		Error_Handler();
	}

	time.Hours = hour;
	time.Minutes = min;
	time.Seconds = 0;

	res = HAL_RTC_SetTime(&hrtc, &time, RTC_FORMAT_BIN);
	if(res != HAL_OK) {
		Error_Handler();
	}

	return 0;
}
//=========================================================================================================================

//volatile uint8_t keyval=0;

uint8_t JOYstickPOS()
{
	uint8_t	keyval=0;
	keyval = HAL_GPIO_ReadPin (JOYstickPB_GPIO_Port,JOYstickPB_Pin)<<4 ;
	keyval +=		HAL_GPIO_ReadPin (GPIOB, JOYstick4_Pin)<<3 ;
	keyval +=		HAL_GPIO_ReadPin (GPIOB, JOYstick3_Pin)<<2 ;
	keyval +=		HAL_GPIO_ReadPin (GPIOH, JOYstick2_Pin)<<1 ;
	keyval +=		HAL_GPIO_ReadPin (GPIOH, JOYstick1_Pin) ;
	keyval = (~keyval) & 0x1f;

	return keyval;
}
void ledDisp(uint8_t Localval)
{
	if(0x01 & Localval)
		HAL_GPIO_WritePin(GPIOC, LED1_Pin, GPIO_PIN_SET);
	else
		HAL_GPIO_WritePin(GPIOC, LED1_Pin, GPIO_PIN_RESET);
	if(0x02 & Localval)
		HAL_GPIO_WritePin(GPIOC, LED2_Pin, GPIO_PIN_SET);
	else
		HAL_GPIO_WritePin(GPIOC, LED2_Pin, GPIO_PIN_RESET);
	if(0x04 & Localval)
		HAL_GPIO_WritePin(GPIOC, LED3_Pin, GPIO_PIN_SET);
	else
		HAL_GPIO_WritePin(GPIOC, LED3_Pin, GPIO_PIN_RESET);
	if(0x08 & Localval)
		HAL_GPIO_WritePin(GPIOA, LED4_Pin, GPIO_PIN_SET);
	else
		HAL_GPIO_WritePin(GPIOA, LED4_Pin, GPIO_PIN_RESET);
	if(0x10 & Localval)
		HAL_GPIO_WritePin(GPIOA, LED5_Pin, GPIO_PIN_SET);
	else
		HAL_GPIO_WritePin(GPIOA, LED5_Pin, GPIO_PIN_RESET);
	if(0x20 & Localval)
		HAL_GPIO_WritePin(GPIOA, LED6_Pin, GPIO_PIN_SET);
	else
		HAL_GPIO_WritePin(GPIOA, LED6_Pin, GPIO_PIN_RESET);
	if(0x40 & Localval)
		HAL_GPIO_WritePin(GPIOA, LED7_Pin, GPIO_PIN_SET);
	else
		HAL_GPIO_WritePin(GPIOA, LED7_Pin, GPIO_PIN_RESET);
	if(0x80 & Localval)
		HAL_GPIO_WritePin(GPIOA, LED8_Pin, GPIO_PIN_SET);
	else
		HAL_GPIO_WritePin(GPIOA, LED8_Pin, GPIO_PIN_RESET);

}
void setTime()
{
	int8_t Jsp=0,TimeItem=0;
	int8_t TimeArray[12];
	RTC_DateTypeDef FILEdate;
	RTC_TimeTypeDef FILEtime;
	HAL_StatusTypeDef res;

	ssd1306_Clear();

	res = HAL_RTC_GetTime(&hrtc, &FILEtime, RTC_FORMAT_BIN);
	if(res != HAL_OK) {
		Error_Handler();
	}

	res = HAL_RTC_GetDate(&hrtc, &FILEdate, RTC_FORMAT_BIN);
	if(res != HAL_OK) {
		Error_Handler();
	}
    TimeArray[0] =(FILEdate.Year  /10) %10;
    TimeArray[1] =(FILEdate.Year - TimeArray[0])%10;

    TimeArray[2] =(FILEdate.Month /10)%10;
    TimeArray[3] =(FILEdate.Month - TimeArray[2])%10;

    TimeArray[4] =(FILEdate.Date /10)%10;
    TimeArray[5] =(FILEdate.Date - TimeArray[4])%10;

    TimeArray[6] =(FILEtime.Hours /10)%10;
    TimeArray[7] =(FILEtime.Hours - TimeArray[6])%10;

    TimeArray[8] =(FILEtime.Minutes /10)%10;
    TimeArray[9] =(FILEtime.Minutes - TimeArray[8])%10;

	while (1)
	{
		sprintf(rtext, "%4d / %2d / %2d",
				2000+TimeArray[0]*10+TimeArray[1],
				TimeArray[2]*10+TimeArray[3],
				TimeArray[4]*10+TimeArray[5]);
		LCD_ShowString(2, 0, 6,8 , White, rtext);
		sprintf(rtext," %2d:%2d",
				TimeArray[6]*10+TimeArray[7],
				TimeArray[8]*10+TimeArray[9]);
		LCD_ShowString(2, FontH*2, 6,8 , White, rtext);
		Jsp = JOYstickPOS();
		HAL_Delay(25);
		switch (Jsp){
		case (1):{   //R
			if (TimeItem == 9) {TimeItem = 0;} else TimeItem++ ;
			break;
		}
		case (4):{  //L
			if (TimeItem>0) {TimeItem-- ;}
			else MenuItem =9;
			break;
		}
		case (16):{ //UP
			TimeArray[TimeItem] == 9 ? TimeArray[TimeItem]=0: TimeArray[TimeItem]++;
			break;
		}
		case (8):{ //DN
			TimeArray[TimeItem] == 0 ? TimeArray[TimeItem]=9 :TimeArray[TimeItem]--;
			break;
		}
		case (2):{
			RTC_Set(TimeArray[0]*10+TimeArray[1],
					TimeArray[2]*10+TimeArray[3],
					TimeArray[4]*10+TimeArray[5],
					TimeArray[6]*10+TimeArray[7],
					TimeArray[8]*10+TimeArray[9]);

			ssd1306_Clear();

			return;
			break;
		}

		}

	}

}
//=========================================================================================================================

void *memset16(void *m, uint16_t val, size_t count)
{
	uint16_t *buf = m;

	while(count--) *buf++ = val;
	return m;
}

//=========================================================================================================================
void ProcessBlock()
{
	uint32_t hist[128];
	uint32_t sharp[128];
	memset(hist,0,128*sizeof(uint32_t));
	memset(sharp,0,128*sizeof(uint32_t));
	uint32_t CS = CurrentSlot %SLOTS ? (CurrentSlot-2) %SLOTS : CurrentSlot %SLOTS ;
	uint16_t *linptr = (uint16_t *)(SDRAMAREA+((CS%SLOTS)*(Npixels*2)));
	uint32_t norm =0;//,zero=0;
	uint32_t pindex;
	uint32_t partialdiff;//,oldp;

	for (int i=0 ; i < Npixels ;i++){
		pindex = linptr[i];

		pindex = pindex>>9; //segments of 128(of 65536)
		if (pindex > 127) pindex = 127;
		hist[pindex]++;

		if (norm < hist[pindex])
			  norm = hist[pindex]; //find local max

		partialdiff = abs((int32_t)linptr[i] - (int32_t)linptr[i+1]);
		if (partialdiff > sharp[i/(Npixels>>7)] )
			sharp[i/(Npixels>>7)] = partialdiff;
	}
	ssd1306_Clear();

	for (int i=0 ;i<128;i++){
		if (hist[i] != 0)
		{
			uint32_t v= hist[i]*48/norm;
			ssd1306_DrawVerticalLine(i, (int16_t)48-v ,(int16_t) v);
		}
		uint32_t w = sharp[i]>>10;
		ssd1306_DrawVerticalLine(i, (int16_t)64-w ,(int16_t) w);

	}

	ssd1306_UpdateScreen();

	//	printf("norm %d , Zeros %d\n",norm,zero);

}
//=========================================================================================================================
void Histo()
{
	ssd1306_Clear();
	//HAL_GPIO_WritePin(REDled_GPIO_Port, REDled_Pin, GPIO_PIN_SET); //Clear Error light
	TransferComplete7=0;
	TransferCompleteelse=0;
			if (HAL_OK !=  HAL_TIM_PWM_Stop(&htim1, TIM_CHANNEL_1))Error_Handler(); //reload Exposure& Length
			if (HAL_OK !=  HAL_TIM_PWM_Stop(&htim1, TIM_CHANNEL_2))Error_Handler(); //reload Exposure& Length
			if (HAL_OK !=  HAL_TIM_PWM_Stop(&htim1, TIM_CHANNEL_3))Error_Handler(); //reload Exposure& Length
//			HAL_TIM_Base_Stop(&htim1);
//			HAL_TIM_Base_Stop_IT(&htim1);

	htim1.Init.Period = (Exposure*TIMEDenom/TIMENumer)-1;
	htim1.Init.RepetitionCounter = NumLines-1;
	if (HAL_TIM_Base_Init(&htim1) != HAL_OK)Error_Handler();

	Sequence=SEQ_Running;
	CurrentSlot=0;
	LastWrittenSlot=0;
	HAL_TIM_Base_Start(&htim2);HAL_TIM_Base_Start(&htim3);HAL_TIM_Base_Start(&htim8);

	if (HAL_OK !=   HAL_TIM_PWM_Start(&htim1, TIM_CHANNEL_1))Error_Handler();
	if (HAL_OK !=   HAL_TIM_PWM_Start(&htim1, TIM_CHANNEL_2))Error_Handler();
	if (HAL_OK !=   HAL_TIM_PWM_Start(&htim1, TIM_CHANNEL_3))Error_Handler();
//	HAL_TIM_Base_Start(&htim1);
//	HAL_TIM_Base_Start_IT(&htim1);

	HAL_Delay(80);
	oldState = GPIO_PIN_SET;
	{
		while(RunState != HALT && (SEQ_Complete != Sequence)){
			if (CurrentSlot >2)ProcessBlock();
			if (0 != JOYstickPOS()){
				RunState = HALT;
				Sequence=SEQ_Complete;
			}
		}

	}
	TrialEnd();

}//complete

//----------------------------------------------------------------------------
void TrialStart()
{
	if( SDstate == SDnotopen)
	{
		ssd1306_Clear();
//		IRQCNT_HAL_UART_TxCpltCallback=0;
		IRQCNT_HAL_ADC_ConvCpltCallback=0;
//		IRQCNT_HAL_TIM_PeriodElapsedHalfCpltCallback1=0;
//		IRQCNT_HAL_TIM_PeriodElapsedHalfCpltCallback2=0;
//		IRQCNT_HAL_TIM_PeriodElapsedHalfCpltCallback3=0;
//		IRQCNT_HAL_TIM_PeriodElapsedHalfCpltCallback8=0;
//		IRQCNT_HAL_TIM_PeriodElapsedCallback1=0;
//		IRQCNT_HAL_TIM_PeriodElapsedCallback2=0;
//		IRQCNT_HAL_TIM_PeriodElapsedCallback3=0;
//		IRQCNT_HAL_TIM_PeriodElapsedCallback8=0;
//		IRQCNT_HAL_TIM_TriggerCallback1=0;
//		IRQCNT_HAL_TIM_TriggerCallback2=0;
//		IRQCNT_HAL_TIM_TriggerCallback3=0;
//		IRQCNT_HAL_TIM_TriggerCallback8=0;
//		HAL_GPIO_WritePin(REDled_GPIO_Port, REDled_Pin, GPIO_PIN_SET); //Clear Error light
		TransferComplete7=0;
		TransferCompleteelse=0;
		DACval=0;BuffDiffMax=0;
#ifdef DISK
		f_err_code = f_mount( &FATFS_Obj, (TCHAR const*)SDPath,0);
		if (f_err_code != FR_OK )
		{
			printf("Diskerror%d /n",f_err_code);
			{
				Error_Handler();
			}
		}
#endif
		HAL_TIM_Base_Start(&htim2);HAL_TIM_Base_Start(&htim3);HAL_TIM_Base_Start(&htim8);

				if (HAL_OK !=  HAL_TIM_PWM_Stop(&htim1, TIM_CHANNEL_1))Error_Handler(); //reload Exposure& Length
				if (HAL_OK !=  HAL_TIM_PWM_Stop(&htim1, TIM_CHANNEL_2))Error_Handler(); //reload Exposure& Length
				if (HAL_OK !=  HAL_TIM_PWM_Stop(&htim1, TIM_CHANNEL_3))Error_Handler(); //reload Exposure& Length
//				HAL_TIM_Base_Stop(&htim1);
//				HAL_TIM_Base_Stop_IT(&htim1);

		htim1.Init.Period = (Exposure*TIMEDenom/TIMENumer)-1;
		htim1.Init.RepetitionCounter = NumLines-1;
		if (HAL_TIM_Base_Init(&htim1) != HAL_OK)Error_Handler();

		RTC_DateTypeDef FILEdate;
		HAL_StatusTypeDef res;

		res = HAL_RTC_GetTime(&hrtc, &Filetime, RTC_FORMAT_BIN);
		if(res != HAL_OK) Error_Handler();

		res = HAL_RTC_GetDate(&hrtc, &FILEdate, RTC_FORMAT_BIN);
		if(res != HAL_OK) Error_Handler();

		HAL_Delay(800);

		sprintf((char *)rtext,"0:%02d%02d%02d%02d%02d%02d_%02d.pgm",
				FILEdate.Year,
				FILEdate.Month,
				FILEdate.Date,
				Filetime.Hours,
				Filetime.Minutes,
				Filetime.Seconds,
				SelectNEStateValue[SelectNEState]/1000);
#ifdef DISK
		f_err_code = f_open(&fp,( char *)rtext,FA_CREATE_ALWAYS | FA_READ | FA_WRITE);
		HAL_Delay(800);
		if (f_err_code != 		FR_OK	){
			LCD_ShowString(2, 0, 6,8, White, "FC Error");
			f_close(&fp);
			Error_Handler();
		}
//
//		sprintf((char *)fileHeadertext,"P5 %5d %5d 65535 ", Npixels,SelectNLStateValue[SelectNLState] );
//		int hlen = strlen(fileHeadertext);
//		res = f_write ( &fp,
//				(const void*) fileHeadertext ,
//				hlen ,
//				(void *)&BytesWritten);
//		if (res  != 0 || (BytesWritten != (hlen))	){
//			LCD_ShowString(2, 0, 6,8,White, "FW Error");
//			f_close(&fp);
//			Error_Handler();
//		}

#endif
		secStart=((uint32_t)Filetime.Hours*3600)+((uint32_t)Filetime.Minutes*60)+(uint32_t)Filetime.Seconds;
		LCD_ShowString(2, FontH, 6, 8, White,rtext);

		SDstate=SDopen;
		sprintf((char *)rtext,"Run %d %d  ",SelectNEStateValue[SelectNEState],SelectNLStateValue[SelectNLState]);
		LCD_ShowString(2, 0, 6,8 , White, rtext);
		NumberOfWrites =0;
		Sequence=SEQ_Running;

		CurrentSlot=0;
		LastWrittenSlot=0;
		HAL_TIM_Base_Start(&htim2);HAL_TIM_Base_Start(&htim3);HAL_TIM_Base_Start(&htim8);
			if (HAL_OK !=   HAL_TIM_PWM_Start(&htim1, TIM_CHANNEL_1))Error_Handler();
			if (HAL_OK !=   HAL_TIM_PWM_Start(&htim1, TIM_CHANNEL_2))Error_Handler();
			if (HAL_OK !=   HAL_TIM_PWM_Start(&htim1, TIM_CHANNEL_3))Error_Handler();
//			HAL_TIM_Base_Start(&htim1);
//			HAL_TIM_Base_Start_IT(&htim1);

		oldState = GPIO_PIN_SET;
	}
}
//=========================================================================================================================
void TrialEnd()
{
	if (SDstate == SDopen)
	{
#ifdef DISK
		f_close(&fp);
#endif
	}

			if (HAL_OK !=  HAL_TIM_PWM_Stop(&htim1, TIM_CHANNEL_1))Error_Handler(); //reload Exposure& Length
			if (HAL_OK !=  HAL_TIM_PWM_Stop(&htim1, TIM_CHANNEL_2))Error_Handler(); //reload Exposure& Length
			if (HAL_OK !=  HAL_TIM_PWM_Stop(&htim1, TIM_CHANNEL_3))Error_Handler(); //reload Exposure& Length
			HAL_TIM_Base_Stop(&htim2);HAL_TIM_Base_Stop(&htim3);HAL_TIM_Base_Stop(&htim8);
//			HAL_TIM_Base_Stop(&htim1);
//			HAL_TIM_Base_Stop_IT(&htim1);

}
//=========================================================================================================================
void TrialComplete()
{
	if (SDstate == SDopen)
	{
		{

			FRESULT res;
			//			SD_WriteStartTime;
			BuffDiff=(CurrentSlot)-(LastWrittenSlot);

			while ((CurrentSlot)> (LastWrittenSlot) && (RunState != HALT))
			{
#ifdef DISK

				res = f_write ( &fp,														/* Pointer to the file object */
						(const void*) (SDRAMAREA+((LastWrittenSlot%SLOTS)*(Npixels*2))),	/* Pointer to the data to be written */
						(Npixels*2),														/* Number of bytes to write */
						(void *)&BytesWritten										/* Pointer to number of bytes written */
				);
				if (res  != FR_OK || (BytesWritten !=(Npixels*2))	){
					LCD_ShowString(2, 0, 6,8,White, "FW Error");
					f_close(&fp);
					Error_Handler();
				}
#endif
				LastWrittenSlot++;
				//				SD_WriteStartTime;
				pixelPlace=((LastWrittenSlot <<7) / NumLines);
				if (pixelPlaceOld != pixelPlace){
					ssd1306_DrawPixel(pixelPlace, 62);
					HAL_GPIO_TogglePin(BLUEled_GPIO_Port, BLUEled_Pin);
					ssd1306_UpdateScreen();
					pixelPlaceOld = pixelPlace;
				}
				if (0 != JOYstickPOS()){
					RunState = HALT;
				}

			}
		}
		TrialEnd();
		HAL_StatusTypeDef res = HAL_RTC_GetTime(&hrtc, &timeEnd, RTC_FORMAT_BIN);
		if(res != HAL_OK) {
			Error_Handler();
		}

		uint32_t sec = ((uint32_t)timeEnd.Hours*3600)+((uint32_t)timeEnd.Minutes*60)+((uint32_t)timeEnd.Seconds) -(secStart);
		sprintf(( char *)rtext,"Time %ld sec          ",sec);
		LCD_ShowString(2, 2*FontH,6,8,White,rtext);
		SDstate= SDnotopen;
		RTC_DateTypeDef FILEdate;
		res = HAL_RTC_GetDate(&hrtc, &FILEdate, RTC_FORMAT_BIN);

	}//complete
	Sequence=SEQ_Ready;
	HAL_Delay(100);
	ledDisp(0);
}

//=========================================================================================================================
void TrialOngoing (){

	if (SDstate == SDopen){
		FRESULT res;
		BuffDiff=(CurrentSlot)-(LastWrittenSlot);
		//		SD_WriteStartTime;

		while ((CurrentSlot)> (LastWrittenSlot) ){

#ifdef DISK
			if(LastWrittenSlot == 0 ){
				sprintf((char *)SDRAMAREA,"P5 %5d %5d 65535 ", Npixels,SelectNLStateValue[SelectNLState] );
			}
			res = f_write ( &fp,														/* Pointer to the file object */
					(const void*) (SDRAMAREA+((LastWrittenSlot%SLOTS)*(Npixels*2))),	/* Pointer to the data to be written */
					(Npixels*2),														/* Number of bytes to write */
					(void *)&BytesWritten										/* Pointer to number of bytes written */
			);
			BuffDiff=(CurrentSlot)-(LastWrittenSlot);
			if(BuffDiff > BuffDiffMax)(BuffDiffMax=BuffDiff);
			LastWrittenSlot++;
			NumberOfWrites++;

			if (res  != FR_OK	 || (BytesWritten !=(Npixels*2))	){
				LCD_ShowString(2, 0,6,8,White, "FW Error");
				f_close(&fp);
				Error_Handler();

			}
#endif
			//			SD_WriteStartTime;
			pixelPlace=((LastWrittenSlot <<7) / NumLines);
			if (pixelPlaceOld != pixelPlace){
//				ssd1306_DrawPixel(pixelPlace, 63);
//				ssd1306_DrawPixel(((CurrentSlot <<7) / NumLines), 61);
				HAL_GPIO_TogglePin(BLUEled_GPIO_Port, BLUEled_Pin);
				if (BuffDiff>SLOTS) {
//					HAL_GPIO_WritePin(REDled_GPIO_Port, REDled_Pin, GPIO_PIN_RESET); //error
					RunState = HALT;
					Sequence=SEQ_Complete;

				}
				//if (pixelPlace % 8 == 0)ssd1306_UpdateScreen();
//				ledDisp(1<<((LastWrittenSlot/(NumLines>>3))));
				pixelPlaceOld = pixelPlace;
			}
			ledDisp(((LastWrittenSlot/(NumLines>>8))));

		}
	}
	ADCstate = ADC_idle;
	if (0 != JOYstickPOS()){
		RunState = HALT;
		Sequence=SEQ_Complete;
	}
}
//__-------___________________________________________________________________________________________

void RunMenu()
{
	uint8_t Jsp=0,i=0;
	ssd1306_Clear();
	sprintf(rtext,"RunType:  %c",RunType[SelectRT]);
	LCD_ShowString(2, 0, 6,8 , White, rtext);
	sprintf(rtext,"Exposure: %d",(SelectNEStateValue[SelectNEState]));
	LCD_ShowString(2, FontH, 6,8 , White, rtext);
	sprintf(rtext,"Length:   %d",SelectNLStateValue[SelectNLState]);
	LCD_ShowString(2, 2*FontH, 6,8 , White, rtext);
	ssd1306_DrawVerticalLine(127, MenuItem*FontH,FontH);
	while (RunState == HALT)
	{
		if (i ==0) i=1;
	//ledDisp(i);15
		i<<=1;
		Jsp = JOYstickPOS();

		{
		HAL_Delay(25);
		switch (Jsp){
		case (1):{   //R
			ssd1306_SetColor(Black);
			ssd1306_DrawVerticalLine(127,0,4*FontH);     //Cursur blank
			ssd1306_DrawVerticalLine(126,0,4*FontH);     //Cursur blank
			ssd1306_SetColor(White);
			if (MenuItem == 2) {MenuItem = 0;} else MenuItem++ ;
			ssd1306_DrawVerticalLine(127, MenuItem*FontH,FontH);
			ssd1306_DrawVerticalLine(126, MenuItem*FontH,FontH);
			break;
		}
		case (4):{  //L
			ssd1306_SetColor(Black);
			ssd1306_DrawVerticalLine(127, 0,4*FontH);
			ssd1306_DrawVerticalLine(126, 0,4*FontH);
			ssd1306_SetColor(White);
			if (MenuItem) {MenuItem-- ;}
			else MenuItem =2;
			ssd1306_DrawVerticalLine(127, MenuItem*FontH,FontH);
			ssd1306_DrawVerticalLine(126, MenuItem*FontH,FontH);
			break;
		}
		case (16):{ //UP
			if (MenuItem == 0)
			{
				if (SelectRT == 2) {SelectRT = 0;} else SelectRT++ ;
			}
			else if (MenuItem == 1)
			{
				if (SelectNEState == 5) {SelectNEState = 0;} else SelectNEState++ ;
			}
			else
			{
				if (SelectNLState == 3) {SelectNLState = 0;} else SelectNLState++ ;
			}
			break;
		}
		case (8):{ //DN
			if (MenuItem == 0)
			{
				if(SelectRT) {SelectRT--;} else SelectRT =2;
			}
			else if (MenuItem == 1)
			{
				if (SelectNEState) { SelectNEState--;} else  SelectNEState =5;
			}
			else
			{
				if(SelectNLState) 	{SelectNLState--;}else SelectNLState=3;
			}
			break;
		}
		case (2):{
			if (SelectRT == 0 )
				RunState = CONTINUOUS;
			else if (SelectRT == 1 )
				RunState = SINGLE;
			else
				RunState = HISTOGRAM;
			break;
		}

		}
		sprintf(rtext,"RunType:  %c",RunType[SelectRT]);
		LCD_ShowString(2, 0, 6,8 , White, rtext);
		sprintf(rtext,"Exposure: %d    ",(SelectNEStateValue[SelectNEState]));
		LCD_ShowString(2, FontH, 6,8 , White, rtext);
		sprintf(rtext,"Length:   %d    ",SelectNLStateValue[SelectNLState]);
		LCD_ShowString(2, 2*FontH, 6,8 , White, rtext);
	}
	}

}
//__-------___________________________________________________________________________________________

/* USER CODE END 0 */

int main(void)
{

  /* USER CODE BEGIN 1 */
	 FontH = Font_7x10.FontHeight;
  /* USER CODE END 1 */

  /* MCU Configuration--------------------------------------------------------*/

  /* Reset of all peripherals, Initializes the Flash interface and the Systick. */
  HAL_Init();

  /* USER CODE BEGIN Init */

	//	uint8_t cState=2;

  /* USER CODE END Init */

  /* Configure the system clock */
  SystemClock_Config();

  /* USER CODE BEGIN SysInit */
	HAL_I2C_RegisterCallback(&hi2c4,HAL_I2C_MEM_TX_COMPLETE_CB_ID,HAL_I2C_MemTxCpltCallback);

  /* USER CODE END SysInit */

  /* Initialize all configured peripherals */
  MX_GPIO_Init();
  MX_DMA_Init();
  MX_MDMA_Init();
  MX_BDMA_Init();
  MX_TIM3_Init();
  MX_TIM8_Init();
  MX_TIM1_Init();
  MX_TIM2_Init();
  MX_FATFS_Init();
  MX_RTC_Init();
  MX_SDMMC1_SD_Init();
  MX_ADC3_Init();
  MX_FMC_Init();
  MX_I2C4_Init();
  MX_I2C1_Init();
  /* USER CODE BEGIN 2 */
   MX_RTC_InitAlt();

  //	HAL_GPIO_WritePin(SensorPWRenable_GPIO_Port, SensorPWRenable_Pin, GPIO_PIN_RESET);
	MX_GPIO2Init();  //pullups for keypad

	for(int i=1; i<128; i++)
	{
		int ret = HAL_I2C_IsDeviceReady(&hi2c4, (uint16_t)(i<<1), 3, 5);
		if (ret != HAL_OK) /* No ACK Received At That Address */
		{
			// HAL_UART_Transmit(&huart2, Space, sizeof(Space), 10000);
		}
		else if(ret == HAL_OK)
		{
			sprintf(rtext, "0x%X", i);
			//    HAL_UART_Transmit(&huart2, Buffer, sizeof(Buffer), 10000);
		}
	}
	HAL_I2C_RegisterCallback(&hi2c4,HAL_I2C_MEM_TX_COMPLETE_CB_ID,HAL_I2C_MemTxCpltCallback);

	ssd1306_Init();
//	HAL_GPIO_WritePin(REDled_GPIO_Port, REDled_Pin, GPIO_PIN_SET);
	ledDisp(255);
	sprintf(rtext," Hellow World");
	LCD_ShowString(2, 0, 6,8, White, rtext);
	LCD_ShowString(2, 2*FontH, 6,8, White, rtext);
	LCD_ShowString(2, 4*FontH, 6,8, White, rtext);
	LCD_ShowString(2, 6*FontH, 6,8, White, rtext);
	ledDisp(0);

	memTest();

#ifdef DISK
	if(BSP_SD_Init()!=0)
	{
		HAL_Delay(5);
	}
	if(disk_initialize(0) != RES_OK)
	{
		HAL_Delay(5);
	}
#endif
	if(HAL_ADCEx_Calibration_Start(&hadc3, ADC_CALIB_OFFSET, ADC_SINGLE_ENDED) != HAL_OK)	Error_Handler();

	HAL_ADC_RegisterCallback(&hadc3, HAL_ADC_CONVERSION_COMPLETE_CB_ID,HAL_ADC_ConvCpltCallback );
	HAL_ADC_RegisterCallback(&hadc3, HAL_ADC_CONVERSION_HALF_CB_ID,HAL_ADC_ConvHalfCpltCallback );

	HAL_DMA_RegisterCallback(&hdma_memtomem_dma1_stream7, HAL_DMA_XFER_CPLT_CB_ID, TransferComplete);
	HAL_DMA_RegisterCallback(&hdma_memtomem_dma1_stream7, HAL_DMA_XFER_ERROR_CB_ID, TransferError);

	HAL_ADC_Start_DMA(&hadc3,(uint32_t *)dmaBuffer,DMABUFFLEN);

	if (HAL_OK != HAL_TIM_Base_Start_IT(&htim1)) Error_Handler();

	if (HAL_OK !=  HAL_TIM_PWM_Start(&htim2, TIM_CHANNEL_2))Error_Handler();
	if (HAL_OK !=  HAL_TIM_PWM_Start(&htim2, TIM_CHANNEL_1))		Error_Handler();
	if (HAL_OK !=  HAL_TIM_PWM_Start(&htim3, TIM_CHANNEL_1))		Error_Handler();
	if (HAL_OK !=  HAL_TIM_PWM_Start(&htim3, TIM_CHANNEL_2))		Error_Handler();
	if (HAL_OK !=  HAL_TIM_PWM_Start(&htim8, TIM_CHANNEL_1))		Error_Handler();

	//RTC_Set(23, 5, 5, 11,28, 0,5) ;  //CLOCK INITILAIZE

	if (HAL_GPIO_ReadPin (GPIOH, TimeSet_Pin)==0) setTime();
#ifdef ONEPWR
	HAL_GPIO_WritePin(Enable9_GPIO_Port, Enable9_Pin, GPIO_PIN_SET);
	HAL_Delay(500);
	HAL_GPIO_WritePin(SensorPWRenable_GPIO_Port, SensorPWRenable_Pin, GPIO_PIN_RESET); //5v enable signal* 125 boards
	HAL_Delay(500);
#endif
	HAL_Delay(500);

  /* USER CODE END 2 */

  /* Infinite loop */
	while (1)
	{

    /* USER CODE BEGIN 3 */
		RunMenu();
//		RunState = HISTOGRAM;//}{ menu test debug

		Exposure = (SelectNEStateValue[SelectNEState]);
		NumLines = SelectNLStateValue[SelectNLState];
		//
		if (RunState == HISTOGRAM)
		{
#ifndef ONEPWR
			HAL_GPIO_WritePin(Enable9_GPIO_Port, Enable9_Pin, GPIO_PIN_SET);
			HAL_Delay(500);
			HAL_GPIO_WritePin(SensorPWRenable_GPIO_Port, SensorPWRenable_Pin, GPIO_PIN_RESET); //5v enable signal
			HAL_Delay(500);
#endif
			Histo();
#ifndef ONEPWR
			HAL_GPIO_WritePin(SensorPWRenable_GPIO_Port, SensorPWRenable_Pin, GPIO_PIN_SET); //5v disable signal
    		HAL_Delay(250);
			HAL_GPIO_WritePin(Enable9_GPIO_Port, Enable9_Pin, GPIO_PIN_RESET);
		//	HAL_Delay(1000);
#endif
		}
		else{
			//***********************************************************************************************
#ifndef ONEPWR
			HAL_GPIO_WritePin(Enable9_GPIO_Port, Enable9_Pin, GPIO_PIN_SET);
			HAL_Delay(500);
			HAL_GPIO_WritePin(SensorPWRenable_GPIO_Port, SensorPWRenable_Pin, GPIO_PIN_RESET); //5v enable signal
			HAL_Delay(500);
#endif
			do{
				TrialStart();
				while (1){

					if (SEQ_Complete == Sequence){  //================================================================
						TrialComplete();
						sprintf(rtext," Complete          ");
						LCD_ShowString(2, 0, 6,8, White, rtext);
						HAL_Delay(1000);

						break;
					}
					if (ADCstate == ADC_2half && Sequence==SEQ_ONgoing){//============================================
						TrialOngoing();
					}
					if (xferState == Ready){
						xferState = NotReady;
					}

				}//******************************************************************************************************
			}while (RunState == CONTINUOUS);
#ifndef ONEPWR
			HAL_GPIO_WritePin(SensorPWRenable_GPIO_Port, SensorPWRenable_Pin, GPIO_PIN_SET); //5v enable signal
			HAL_Delay(250);
			HAL_GPIO_WritePin(Enable9_GPIO_Port, Enable9_Pin, GPIO_PIN_RESET);
			HAL_Delay(100);
#endif
		}
		RunState = HALT;

		//-----------------------------------------------------------------------------------------------------------------

	}
  /* USER CODE END 3 */
}

void SystemClock_Config(void)
{
  RCC_OscInitTypeDef RCC_OscInitStruct = {0};
  RCC_ClkInitTypeDef RCC_ClkInitStruct = {0};

  /** Supply configuration update enable
  */
  HAL_PWREx_ConfigSupply(PWR_LDO_SUPPLY);

  /** Configure the main internal regulator output voltage
  */
  __HAL_PWR_VOLTAGESCALING_CONFIG(PWR_REGULATOR_VOLTAGE_SCALE1);

  while(!__HAL_PWR_GET_FLAG(PWR_FLAG_VOSRDY)) {}

  /** Configure LSE Drive Capability
  */
  HAL_PWR_EnableBkUpAccess();
  __HAL_RCC_LSEDRIVE_CONFIG(RCC_LSEDRIVE_LOW);

  /** Initializes the RCC Oscillators according to the specified parameters
  * in the RCC_OscInitTypeDef structure.
  */
  RCC_OscInitStruct.OscillatorType = RCC_OSCILLATORTYPE_HSI|RCC_OSCILLATORTYPE_HSE
                              |RCC_OSCILLATORTYPE_LSE;
  RCC_OscInitStruct.HSEState = RCC_HSE_ON;
  RCC_OscInitStruct.LSEState = RCC_LSE_ON;
  RCC_OscInitStruct.HSIState = RCC_HSI_DIV1;
  RCC_OscInitStruct.HSICalibrationValue = RCC_HSICALIBRATION_DEFAULT;
  RCC_OscInitStruct.PLL.PLLState = RCC_PLL_ON;
  RCC_OscInitStruct.PLL.PLLSource = RCC_PLLSOURCE_HSE;
  RCC_OscInitStruct.PLL.PLLM = 5;
  RCC_OscInitStruct.PLL.PLLN = 160;
  RCC_OscInitStruct.PLL.PLLP = 2;
  RCC_OscInitStruct.PLL.PLLQ = 20;
  RCC_OscInitStruct.PLL.PLLR = 2;
  RCC_OscInitStruct.PLL.PLLRGE = RCC_PLL1VCIRANGE_2;
  RCC_OscInitStruct.PLL.PLLVCOSEL = RCC_PLL1VCOWIDE;
  RCC_OscInitStruct.PLL.PLLFRACN = 0;
  if (HAL_RCC_OscConfig(&RCC_OscInitStruct) != HAL_OK)
  {
    Error_Handler();
  }

  /** Initializes the CPU, AHB and APB buses clocks
  */
  RCC_ClkInitStruct.ClockType = RCC_CLOCKTYPE_HCLK|RCC_CLOCKTYPE_SYSCLK
                              |RCC_CLOCKTYPE_PCLK1|RCC_CLOCKTYPE_PCLK2
                              |RCC_CLOCKTYPE_D3PCLK1|RCC_CLOCKTYPE_D1PCLK1;
  RCC_ClkInitStruct.SYSCLKSource = RCC_SYSCLKSOURCE_PLLCLK;
  RCC_ClkInitStruct.SYSCLKDivider = RCC_SYSCLK_DIV1;
  RCC_ClkInitStruct.AHBCLKDivider = RCC_HCLK_DIV2;
  RCC_ClkInitStruct.APB3CLKDivider = RCC_APB3_DIV2;
  RCC_ClkInitStruct.APB1CLKDivider = RCC_APB1_DIV4;
  RCC_ClkInitStruct.APB2CLKDivider = RCC_APB2_DIV4;
  RCC_ClkInitStruct.APB4CLKDivider = RCC_APB4_DIV2;

  if (HAL_RCC_ClockConfig(&RCC_ClkInitStruct, FLASH_LATENCY_2) != HAL_OK)
  {
    Error_Handler();
  }
}

/* USER CODE BEGIN 4 */

void HAL_ADC_ConvCpltCallback (ADC_HandleTypeDef *hadc)
//HAL_ADC_ConvCpltCallback
{
	if (Sequence!=SEQ_Ready){
		//		CPLT_ADC_GPIO;
		xferState = Ready;
		Sequence = SEQ_ONgoing;
		//dmaBuffer = ;
		//		dmaBuffer[0] =(uint32_t ) IRQCNT_HAL_ADC_ConvCpltCallback;
		//		dmaBuffer[1] = (uint32_t )CurrentSlot;
		//		dmaBuffer[2] = (uint32_t )CurrentSlot%SLOTS;
		//		dmaBuffer[3] = (uint32_t )0x0;
		////		dmaBuffer[4] = (uint32_t )0xffffffff;

		HAL_DMA_Start_IT(&hdma_memtomem_dma1_stream7,(uint32_t )dmaBuffer, (uint32_t )(SDRAMAREA+((CurrentSlot%SLOTS)*(Npixels*2))), 2*Npixels*2);
		CurrentSlot+=2;

		IRQCNT_HAL_ADC_ConvCpltCallback++;
		//		CPLT_ADC_GPIO;
	}
}

void HAL_TIM_PeriodElapsedCallback(TIM_HandleTypeDef *htim)
{
	// Check which version of the timer triggered this callback and toggle LED
	if (htim == &htim1)
	{
		//		CPLT_TIM1pe_GPIO;
		if (HAL_OK !=  HAL_TIM_PWM_Stop(&htim1, TIM_CHANNEL_1))		Error_Handler();
		if (HAL_OK !=  HAL_TIM_PWM_Stop(&htim1, TIM_CHANNEL_2))		Error_Handler();
		if (HAL_OK !=  HAL_TIM_PWM_Stop(&htim1, TIM_CHANNEL_3))		Error_Handler();
//		if (HAL_OK !=  HAL_TIM_PWM_Stop(&htim8, TIM_CHANNEL_1))	Error_Handler();
		if (Sequence!=SEQ_Ready)
			Sequence=SEQ_Complete;
		IRQCNT_HAL_TIM_PeriodElapsedCallback1++;
		//		CPLT_TIM1pe_GPIO;
	}
}

void HAL_TIM_TriggerCallback(TIM_HandleTypeDef *htim)
{
	// Check which version of the timer triggered this callback and toggle LED
	if (htim == &htim1)
	{
		//		TRIGGER_TIM1_GPIO;
		IRQCNT_HAL_TIM_TriggerCallback1++;
		//		TRIGGER_TIM1_GPIO;
	}

}
void TransferComplete(DMA_HandleTypeDef *hdma)
{
	if (hdma == &hdma_memtomem_dma1_stream7){
		//CurrentSlot++;
		if (SEQ_ONgoing == Sequence)
		{
			//			DMA_XFR_CPLT_GPIO;
			ADCstate=ADC_2half;

			//			DMA_XFR_CPLT_GPIO;
		}
		TransferComplete7++;
	}else{
		TransferCompleteelse++;
	}
}
void TransferError(DMA_HandleTypeDef *hdma)
{
	ledDisp(0xE0);
	HAL_Delay(1500);
	if (SDstate == SDopen)
	{
#ifdef DISK
		f_close(&fp);
#endif
	}

	Error_Handler();
}
void Diskerror()
{

	ledDisp(0xD0);
	HAL_Delay(1500);
	if (SDstate == SDopen)
	{
#ifdef DISK
		f_close(&fp);
#endif
	}

	Error_Handler();
}

//
void HAL_GPIO_EXTI_Callback(uint16_t GPIO_Pin)
{
	//	if(GPIO_Pin == nextN_Pin) // INT Source is pin B0
	//	{
	//		NextNFlag = NxtSelectNed; //
	//		HAL_GPIO_EXTI_CallbackNxt++;
	//	}
	//	if(GPIO_Pin == K1_Pin) // INT Source is pin D4
	//	{
	//		K1Flag = 1;
	//		HAL_GPIO_EXTI_CallbackK1++;
	//		f_close(&fp);
	//		Error_Handler();
	//
	//	}
	//	if(GPIO_Pin == SelectN_Pin) // INT Source is pin B1
	//	{
	//		SelectNFlag = SelectNSelectNed;
	//		HAL_GPIO_EXTI_CallbackSelectN++;
	//
	//	}

}

/* USER CODE END 4 */

void Error_Handler(void)
{
  /* USER CODE BEGIN Error_Handler_Debug */
	/* User can add his own implementation to report the HAL error return state */
//	HAL_GPIO_WritePin(REDled_GPIO_Port, REDled_Pin, GPIO_PIN_RESET);
	__disable_irq();
	while (1)
	{
		ledDisp(0xf0);
	}
  /* USER CODE END Error_Handler_Debug */
}
